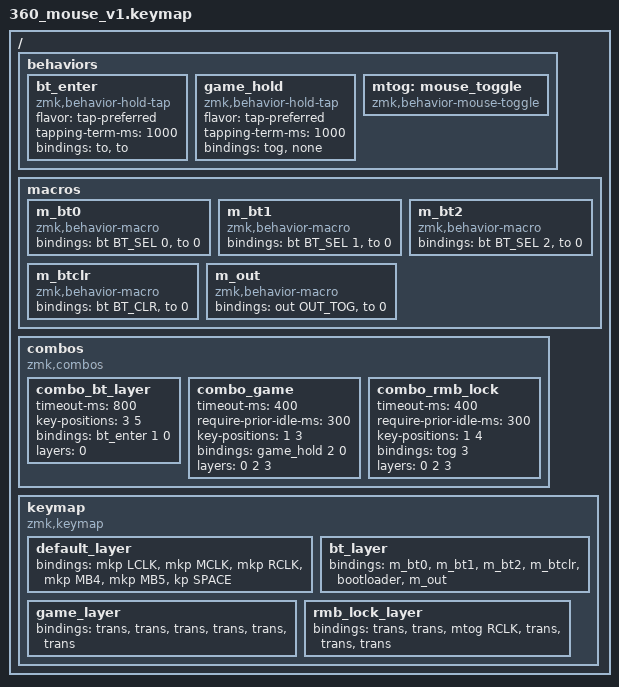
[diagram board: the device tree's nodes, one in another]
#include <behaviors.dtsi>
#include <dt-bindings/zmk/keys.h>
#include <dt-bindings/zmk/mouse.h>
#include <dt-bindings/zmk/bt.h>
#include <dt-bindings/zmk/outputs.h>

/*
 * Layers
 *   0 default   normal mouse, joystick scrolls
 *   1 bt        Bluetooth menu (MB4 + space, hold 1 s)
 *   2 game      joystick sends WASD (MCLK + MB4, hold 1 s, toggles)
 *   3 rmb lock  right button becomes a toggle: click = hold, click = release
 *               (MCLK + MB5 toggles the mode; leaving it releases RMB)
 *
 * Combo positions: 0 left, 1 middle, 2 right, 3 MB4, 4 MB5, 5 space
 */

/ {
    behaviors {
        bt_enter: bt_enter {
            compatible = "zmk,behavior-hold-tap";
            #binding-cells = <2>;
            flavor = "tap-preferred";
            tapping-term-ms = <1000>;
            bindings = <&to>, <&to>;
        };

        /* hold 1 s: toggle game layer; quick tap: nothing */
        game_hold: game_hold {
            compatible = "zmk,behavior-hold-tap";
            #binding-cells = <2>;
            flavor = "tap-preferred";
            tapping-term-ms = <1000>;
            bindings = <&tog>, <&none>;
        };

        /* press: button goes down and stays; press again: released */
        mtog: mouse_toggle {
            compatible = "zmk,behavior-mouse-toggle";
            #binding-cells = <1>;
        };
    };

    macros {
        m_bt0: m_bt0 {
            compatible = "zmk,behavior-macro";
            #binding-cells = <0>;
            bindings = <&bt BT_SEL 0>, <&to 0>;
        };
        m_bt1: m_bt1 {
            compatible = "zmk,behavior-macro";
            #binding-cells = <0>;
            bindings = <&bt BT_SEL 1>, <&to 0>;
        };
        m_bt2: m_bt2 {
            compatible = "zmk,behavior-macro";
            #binding-cells = <0>;
            bindings = <&bt BT_SEL 2>, <&to 0>;
        };
        m_btclr: m_btclr {
            compatible = "zmk,behavior-macro";
            #binding-cells = <0>;
            bindings = <&bt BT_CLR>, <&to 0>;
        };
        m_out: m_out {
            compatible = "zmk,behavior-macro";
            #binding-cells = <0>;
            bindings = <&out OUT_TOG>, <&to 0>;
        };
    };

    combos {
        compatible = "zmk,combos";

        /* MB4 + space, hold 1 s: Bluetooth menu. Off in game mode, so
           MB4 + jump in a game can't be swallowed. */
        combo_bt_layer {
            timeout-ms = <800>;
            key-positions = <3 5>;
            bindings = <&bt_enter 1 0>;
            layers = <0>;
        };

        /* MCLK + MB4, hold 1 s: game mode on/off */
        combo_game {
            timeout-ms = <400>;
            require-prior-idle-ms = <300>;
            key-positions = <1 3>;
            bindings = <&game_hold 2 0>;
            layers = <0 2 3>;
        };

        /* MCLK + MB5: RMB lock mode on/off */
        combo_rmb_lock {
            timeout-ms = <400>;
            require-prior-idle-ms = <300>;
            key-positions = <1 4>;
            bindings = <&tog 3>;
            layers = <0 2 3>;
        };
    };

    keymap {
        compatible = "zmk,keymap";

        default_layer {
            bindings = <&mkp LCLK &mkp MCLK &mkp RCLK &mkp MB4 &mkp MB5 &kp SPACE>;
        };

        bt_layer {
            bindings = <&m_bt0 &m_bt1 &m_bt2 &m_btclr &bootloader &m_out>;
        };

        game_layer {
            bindings = <&trans &trans &trans &trans &trans &trans>;
        };

        rmb_lock_layer {
            bindings = <&trans &trans &mtog RCLK &trans &trans &trans>;
        };
    };
};
